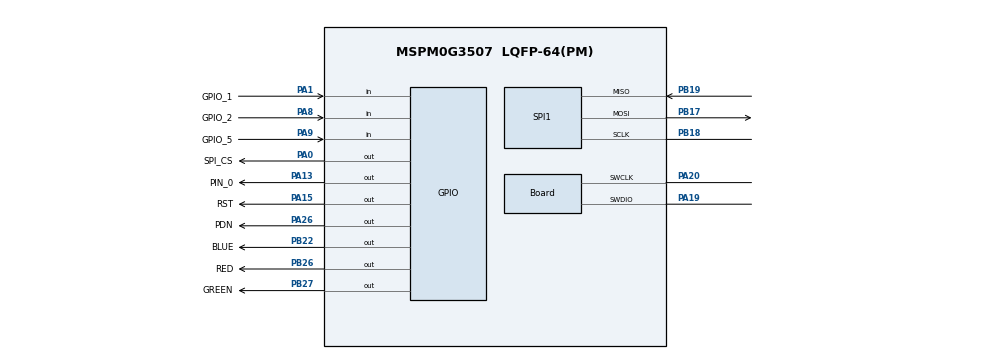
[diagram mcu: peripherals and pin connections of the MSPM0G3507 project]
//@cliArgs --device "MSPM0G350X" --package "LQFP-64(PM)" --part "Default"
//@v2CliArgs --device "MSPM0G3507" --package "LQFP-64(PM)"
// @cliArgs --board /ti/boards/LP_MSPM0G3507 --rtos nortos

/**
 * Import the modules used in this configuration.
 */
const GPIO          = scripting.addModule("/ti/driverlib/GPIO", {}, false);
const GPIO1         = GPIO.addInstance();
const GPIO2         = GPIO.addInstance();
const SPI           = scripting.addModule("/ti/driverlib/SPI", {}, false);
const SPI1          = SPI.addInstance();
const SYSCTL        = scripting.addModule("/ti/driverlib/SYSCTL");
const ProjectConfig = scripting.addModule("/ti/project_config/ProjectConfig");

/**
 * Write custom configuration values to the imported modules.
 */
GPIO1.$name                              = "AFE";
GPIO1.associatedPins.create(6);
GPIO1.associatedPins[0].initialValue     = "SET";
GPIO1.associatedPins[0].$name            = "SPI_CS";
GPIO1.associatedPins[0].pin.$assign      = "PA0";
GPIO1.associatedPins[1].$name            = "RST";
GPIO1.associatedPins[1].initialValue     = "SET";
GPIO1.associatedPins[1].pin.$assign      = "PA15";
GPIO1.associatedPins[2].$name            = "GPIO_1";
GPIO1.associatedPins[2].direction        = "INPUT";
GPIO1.associatedPins[2].pin.$assign      = "PA1";
GPIO1.associatedPins[3].$name            = "GPIO_2";
GPIO1.associatedPins[3].internalResistor = "PULL_DOWN";
GPIO1.associatedPins[3].direction        = "INPUT";
GPIO1.associatedPins[3].interruptEn      = true;
GPIO1.associatedPins[3].polarity         = "RISE";
GPIO1.associatedPins[3].pin.$assign      = "PA8";
GPIO1.associatedPins[4].$name            = "GPIO_5";
GPIO1.associatedPins[4].direction        = "INPUT";
GPIO1.associatedPins[4].pin.$assign      = "PA9";
GPIO1.associatedPins[5].$name            = "PDN";
GPIO1.associatedPins[5].pin.$assign      = "PA26";

const Board                       = scripting.addModule("/ti/driverlib/Board", {}, false);
Board.peripheral.$assign          = "DEBUGSS";
Board.peripheral.swclkPin.$assign = "PA20";
Board.peripheral.swdioPin.$assign = "PA19";

GPIO2.$name                               = "LED";
GPIO2.associatedPins.create(4);
GPIO2.associatedPins[0].launchPadShortcut = "LED2RedEn";
GPIO2.associatedPins[0].$name             = "RED";
GPIO2.associatedPins[0].pin.$assign       = "PB26";
GPIO2.associatedPins[1].launchPadShortcut = "LED2BlueEn";
GPIO2.associatedPins[1].$name             = "BLUE";
GPIO2.associatedPins[1].pin.$assign       = "PB22";
GPIO2.associatedPins[2].$name             = "GREEN";
GPIO2.associatedPins[2].launchPadShortcut = "LED2GreenEn";
GPIO2.associatedPins[2].pin.$assign       = "PB27";
GPIO2.associatedPins[3].$name             = "PIN_0";
GPIO2.associatedPins[3].pin.$assign       = "PA13";

SPI1.rxFifoThreshold                       = "DL_SPI_RX_FIFO_LEVEL_ONE_FRAME";
SPI1.txFifoThreshold                       = "DL_SPI_TX_FIFO_LEVEL_ONE_FRAME";
SPI1.enabledDMAEvent1Triggers              = "DL_SPI_DMA_INTERRUPT_RX";
SPI1.frameFormat                           = "MOTO3";
SPI1.enabledDMAEvent2Triggers              = "DL_SPI_DMA_INTERRUPT_TX";
SPI1.$name                                 = "AFE_SPI";
SPI1.enabledInterrupts                     = ["DMA_DONE_RX","DMA_DONE_TX","TX_EMPTY"];
SPI1.peripheral.$assign                    = "SPI0";
SPI1.peripheral.sclkPin.$assign            = "PB18";
SPI1.peripheral.mosiPin.$assign            = "PB17";
SPI1.peripheral.misoPin.$assign            = "PB19";
SPI1.DMA_CHANNEL_EVENT1.addressMode        = "f2b";
SPI1.DMA_CHANNEL_EVENT1.srcLength          = "BYTE";
SPI1.DMA_CHANNEL_EVENT1.dstLength          = "BYTE";
SPI1.DMA_CHANNEL_EVENT1.$name              = "DMA_SPI_RX";
SPI1.DMA_CHANNEL_EVENT1.peripheral.$assign = "DMA_CH1";
SPI1.DMA_CHANNEL_EVENT2.srcLength          = "BYTE";
SPI1.DMA_CHANNEL_EVENT2.dstLength          = "BYTE";
SPI1.DMA_CHANNEL_EVENT2.addressMode        = "b2f";
SPI1.DMA_CHANNEL_EVENT2.$name              = "DMA_SPI_TX";
SPI1.DMA_CHANNEL_EVENT2.peripheral.$assign = "DMA_CH0";

SYSCTL.validateClkStatus  = true;
SYSCTL.MCLKSource         = "HSCLK";
SYSCTL.SYSPLL_CLK0En      = true;
SYSCTL.peripheral.$assign = "SYSCTL";

ProjectConfig.migrationCondition = true;
ProjectConfig.genLibCMSIS        = true;
